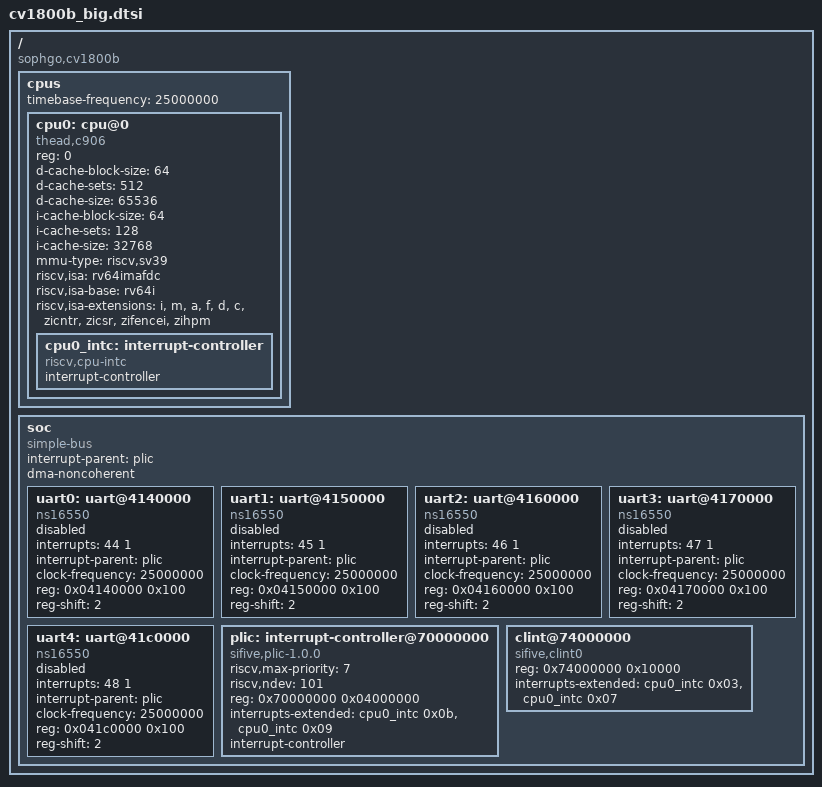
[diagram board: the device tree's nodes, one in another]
// SPDX-License-Identifier: (GPL-2.0 OR MIT)
/*
 * Copyright (C) 2024 Junhui Liu <liujh2818@outlook.com>
 */

/ {
	compatible = "sophgo,cv1800b";
	#address-cells = <1>;
	#size-cells = <1>;

	cpus: cpus {
		#address-cells = <1>;
		#size-cells = <0>;
		timebase-frequency = <25000000>;

		cpu0: cpu@0 {
			compatible = "thead,c906", "riscv";
			device_type = "cpu";
			reg = <0>;
			d-cache-block-size = <64>;
			d-cache-sets = <512>;
			d-cache-size = <65536>;
			i-cache-block-size = <64>;
			i-cache-sets = <128>;
			i-cache-size = <32768>;
			mmu-type = "riscv,sv39";
			riscv,isa = "rv64imafdc";
			riscv,isa-base = "rv64i";
			riscv,isa-extensions = "i", "m", "a", "f", "d", "c", "zicntr", "zicsr",
					       "zifencei", "zihpm";

			cpu0_intc: interrupt-controller {
				compatible = "riscv,cpu-intc";
				interrupt-controller;
				#interrupt-cells = <1>;
			};
		};
	};

	soc {
		compatible = "simple-bus";
		interrupt-parent = <&plic>;
		#address-cells = <1>;
		#size-cells = <1>;
		dma-noncoherent;
		ranges;

		uart0: uart@4140000 {
			interrupts = < 44 1 >;
			interrupt-parent = < &plic >;
			clock-frequency = < 25000000 >;
			reg = < 0x04140000 0x100 >;
			compatible = "ns16550";
			reg-shift = < 2 >;
			status = "disabled";
		};

		uart1: uart@4150000 {
			interrupts = < 45 1 >;
			interrupt-parent = < &plic >;
			clock-frequency = < 25000000 >;
			reg = < 0x04150000 0x100 >;
			compatible = "ns16550";
			reg-shift = < 2 >;
			status = "disabled";
		};

		uart2: uart@4160000 {
			interrupts = < 46 1 >;
			interrupt-parent = < &plic >;
			clock-frequency = < 25000000 >;
			reg = < 0x04160000 0x100 >;
			compatible = "ns16550";
			reg-shift = < 2 >;
			status = "disabled";
		};

		uart3: uart@4170000 {
			interrupts = < 47 1 >;
			interrupt-parent = < &plic >;
			clock-frequency = < 25000000 >;
			reg = < 0x04170000 0x100 >;
			compatible = "ns16550";
			reg-shift = < 2 >;
			status = "disabled";
		};

		uart4: uart@41c0000 {
			interrupts = < 48 1 >;
			interrupt-parent = < &plic >;
			clock-frequency = < 25000000 >;
			reg = < 0x041c0000 0x100 >;
			compatible = "ns16550";
			reg-shift = < 2 >;
			status = "disabled";
		};

		plic: interrupt-controller@70000000 {
			riscv,max-priority = <7>;
			riscv,ndev = < 101 >;
			reg = <0x70000000 0x04000000>;
			interrupts-extended = <&cpu0_intc 0x0b &cpu0_intc 0x09>;
			interrupt-controller;
			compatible = "sifive,plic-1.0.0";
			#address-cells = < 0x00 >;
			#interrupt-cells = < 0x02 >;
		};

		clint@74000000 {
			compatible = "sifive,clint0";
			reg = <0x74000000 0x10000>;
			interrupts-extended = <&cpu0_intc 0x03 &cpu0_intc 0x07>;
		};
	};
};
